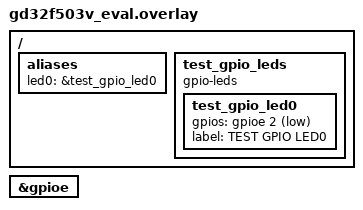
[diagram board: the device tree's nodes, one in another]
/*
 * Copyright (c) 2026 GigaDevice Semiconductor Inc.
 *
 * SPDX-License-Identifier: Apache-2.0
 */

/*
 * The board led0 (PC8) drives an active-high LED, which keeps the pin at the
 * wrong level under an internal pull-down and makes the single-ended subtest
 * skip. Re-alias led0 to a free, floating, active-low pin instead.
 */

/ {
	aliases {
		led0 = &test_gpio_led0;
	};

	test_gpio_leds {
		compatible = "gpio-leds";

		test_gpio_led0: test_gpio_led0 {
			gpios = <&gpioe 2 GPIO_ACTIVE_LOW>;
			label = "TEST GPIO LED0";
		};
	};
};

&gpioe {
	status = "okay";
};
